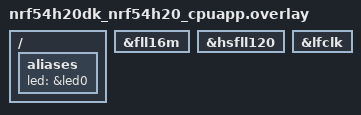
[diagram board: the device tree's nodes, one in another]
/*
 * Copyright (c) 2025 Nordic Semiconductor ASA
 *
 * SPDX-License-Identifier: LicenseRef-Nordic-5-Clause
 */

/ {
	aliases {
		led = &led0;
		/delete-property/ led1;
	};
};

/delete-node/ &led1;

&fll16m {
	status = "okay";
};

&hsfll120 {
	status = "okay";
};

&lfclk {
	status = "okay";
};
